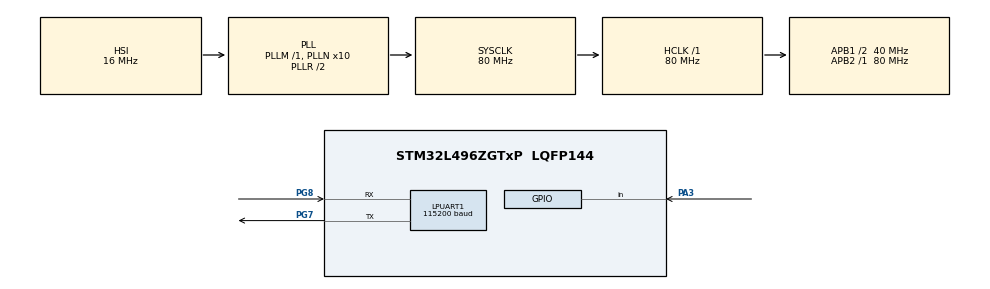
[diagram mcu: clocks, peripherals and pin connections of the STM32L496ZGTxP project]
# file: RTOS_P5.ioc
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FREERTOS.Mutexes01=myMutex01,Dynamic,NULL,Available
FREERTOS.RecursiveMutexes01=myRecursiveMutex01,Dynamic,NULL,Available
FREERTOS.Tasks01=LPT,16,512,StartLPT,Default,NULL,Dynamic,NULL,NULL;MPT,24,512,StartMPT,Default,NULL,Dynamic,NULL,NULL;HPT,32,512,StartHPT,Default,NULL,Dynamic,NULL,NULL;VHPT,40,512,StartVHPT,Default,NULL,Dynamic,NULL,NULL
FREERTOS.configTOTAL_HEAP_SIZE=10000
FREERTOS.configUSE_NEWLIB_REENTRANT=1
LPUART1.BaudRate=115200
LPUART1.WordLength=UART_WORDLENGTH_8B
Mcu.Family=STM32L4
Mcu.Name=STM32L496ZGTxP
Mcu.Package=LQFP144
NVIC.PriorityGroup=NVIC_PRIORITYGROUP_4
NVIC.TIM6_DAC_IRQn=true\:15\:0\:false\:false\:true\:false\:false\:true\:true
NVIC.TimeBase=TIM6_DAC_IRQn
NVIC.TimeBaseIP=TIM6
PA13\ (JTMS/SWDIO).Mode=Serial_Wire
PA13\ (JTMS/SWDIO).Signal=SYS_JTMS-SWDIO
PA14\ (JTCK/SWCLK).Mode=Serial_Wire
PA14\ (JTCK/SWCLK).Signal=SYS_JTCK-SWCLK
PA3.GPIO_PuPd=GPIO_PULLUP
PA3.Signal=GPIO_Input
PG7.Mode=Asynchronous
PG7.Signal=LPUART1_TX
PG8.Mode=Asynchronous
PG8.Signal=LPUART1_RX
ProjectManager.HeapSize=0x200
ProjectManager.StackSize=0x400
ProjectManager.TargetToolchain=STM32CubeIDE
RCC.48MHZClocksFreq_Value=24000000
RCC.ADCFreq_Value=64000000
RCC.AHBFreq_Value=80000000
RCC.APB1CLKDivider=RCC_HCLK_DIV2
RCC.APB1Freq_Value=40000000
RCC.APB1TimFreq_Value=80000000
RCC.APB2Freq_Value=80000000
RCC.APB2TimFreq_Value=80000000
RCC.CortexFreq_Value=80000000
RCC.HCLKFreq_Value=80000000
RCC.HSE_VALUE=8000000
RCC.HSI48_VALUE=48000000
RCC.HSI_VALUE=16000000
RCC.LSE_VALUE=32768
RCC.MSI_VALUE=4000000
RCC.PLLMUL=RCC_PLL_MUL9
RCC.PLLN=10
RCC.PLLSourceVirtual=RCC_PLLSOURCE_HSI
RCC.PRESCALERUSB=RCC_USBCLKSOURCE_PLL_DIV1_5
RCC.SYSCLKFreq_VALUE=80000000
RCC.SYSCLKSource=RCC_SYSCLKSOURCE_PLLCLK
RCC.SYSCLKSourceVirtual=RCC_SYSCLKSOURCE_PLLCLK
RCC.USBFreq_Value=64000000
RCC.VCOOutputFreq_Value=160000000
VP_FREERTOS_VS_CMSIS_V2.Mode=CMSIS_V2
VP_SYS_VS_tim6.Mode=TIM6
board=NUCLEO-L496ZG-P

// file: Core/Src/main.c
/* USER CODE BEGIN Header */
/**
  ******************************************************************************
  * @file           : main.c
  * @brief          : Main program body
  ******************************************************************************
  * @attention
  *
  * Copyright (c) 2026 STMicroelectronics.
  * All rights reserved.
  *
  * This software is licensed under terms that can be found in the LICENSE file
  * in the root directory of this software component.
  * If no LICENSE file comes with this software, it is provided AS-IS.
  *
  ******************************************************************************
  */
/* USER CODE END Header */
#include "main.h"
#include "cmsis_os.h"

/* USER CODE BEGIN Includes */
#include "stdio.h"
#include "string.h"
/* USER CODE END Includes */

UART_HandleTypeDef hlpuart1;

/* Definitions for LPT */
osThreadId_t LPTHandle;
const osThreadAttr_t LPT_attributes = {
  .name = "LPT",
  .stack_size = 512 * 4,
  .priority = (osPriority_t) osPriorityBelowNormal,
};
/* Definitions for MPT */
osThreadId_t MPTHandle;
const osThreadAttr_t MPT_attributes = {
  .name = "MPT",
  .stack_size = 512 * 4,
  .priority = (osPriority_t) osPriorityNormal,
};
/* Definitions for HPT */
osThreadId_t HPTHandle;
const osThreadAttr_t HPT_attributes = {
  .name = "HPT",
  .stack_size = 512 * 4,
  .priority = (osPriority_t) osPriorityAboveNormal,
};
/* Definitions for VHPT */
osThreadId_t VHPTHandle;
const osThreadAttr_t VHPT_attributes = {
  .name = "VHPT",
  .stack_size = 512 * 4,
  .priority = (osPriority_t) osPriorityHigh,
};
/* Definitions for myMutex01 */
osMutexId_t myMutex01Handle;
const osMutexAttr_t myMutex01_attributes = {
  .name = "myMutex01"
};
/* Definitions for myRecursiveMutex01 */
osMutexId_t myRecursiveMutex01Handle;
const osMutexAttr_t myRecursiveMutex01_attributes = {
  .name = "myRecursiveMutex01",
  .attr_bits = osMutexRecursive,
};

void SystemClock_Config(void);
static void MX_GPIO_Init(void);
static void MX_LPUART1_UART_Init(void);
void StartLPT(void *argument);
void StartMPT(void *argument);
void StartHPT(void *argument);
void StartVHPT(void *argument);

/* USER CODE BEGIN 0 */

int __io_putchar (int ch)
{
	uint8_t c = ch;
	HAL_UART_Transmit(&hlpuart1, &c, 1, HAL_MAX_DELAY);
	return ch;
}

/* USER CODE END 0 */

int main(void)
{

  /* MCU Configuration--------------------------------------------------------*/

  /* Reset of all peripherals, Initializes the Flash interface and the Systick. */
  HAL_Init();

  /* Configure the system clock */
  SystemClock_Config();

  /* Initialize all configured peripherals */
  MX_GPIO_Init();
  MX_LPUART1_UART_Init();

  /* Init scheduler */
  osKernelInitialize();
  /* Create the mutex(es) */
  /* creation of myMutex01 */
  myMutex01Handle = osMutexNew(&myMutex01_attributes);

  /* Create the recursive mutex(es) */
  /* creation of myRecursiveMutex01 */
  myRecursiveMutex01Handle = osMutexNew(&myRecursiveMutex01_attributes);

  /* Create the thread(s) */
  /* creation of LPT */
  LPTHandle = osThreadNew(StartLPT, NULL, &LPT_attributes);

  /* creation of MPT */
  MPTHandle = osThreadNew(StartMPT, NULL, &MPT_attributes);

  /* creation of HPT */
  HPTHandle = osThreadNew(StartHPT, NULL, &HPT_attributes);

  /* creation of VHPT */
  VHPTHandle = osThreadNew(StartVHPT, NULL, &VHPT_attributes);

  /* Start scheduler */
  osKernelStart();

  /* We should never get here as control is now taken by the scheduler */

  /* Infinite loop */
  while (1)
  {

  }
}

void SystemClock_Config(void)
{
  RCC_OscInitTypeDef RCC_OscInitStruct = {0};
  RCC_ClkInitTypeDef RCC_ClkInitStruct = {0};

  /** Configure the main internal regulator output voltage
  */
  if (HAL_PWREx_ControlVoltageScaling(PWR_REGULATOR_VOLTAGE_SCALE1) != HAL_OK)
  {
    Error_Handler();
  }

  /** Initializes the RCC Oscillators according to the specified parameters
  * in the RCC_OscInitTypeDef structure.
  */
  RCC_OscInitStruct.OscillatorType = RCC_OSCILLATORTYPE_HSI;
  RCC_OscInitStruct.HSIState = RCC_HSI_ON;
  RCC_OscInitStruct.HSICalibrationValue = RCC_HSICALIBRATION_DEFAULT;
  RCC_OscInitStruct.PLL.PLLState = RCC_PLL_ON;
  RCC_OscInitStruct.PLL.PLLSource = RCC_PLLSOURCE_HSI;
  RCC_OscInitStruct.PLL.PLLM = 1;
  RCC_OscInitStruct.PLL.PLLN = 10;
  RCC_OscInitStruct.PLL.PLLP = RCC_PLLP_DIV2;
  RCC_OscInitStruct.PLL.PLLQ = RCC_PLLQ_DIV2;
  RCC_OscInitStruct.PLL.PLLR = RCC_PLLR_DIV2;
  if (HAL_RCC_OscConfig(&RCC_OscInitStruct) != HAL_OK)
  {
    Error_Handler();
  }

  /** Initializes the CPU, AHB and APB buses clocks
  */
  RCC_ClkInitStruct.ClockType = RCC_CLOCKTYPE_HCLK|RCC_CLOCKTYPE_SYSCLK
                              |RCC_CLOCKTYPE_PCLK1|RCC_CLOCKTYPE_PCLK2;
  RCC_ClkInitStruct.SYSCLKSource = RCC_SYSCLKSOURCE_PLLCLK;
  RCC_ClkInitStruct.AHBCLKDivider = RCC_SYSCLK_DIV1;
  RCC_ClkInitStruct.APB1CLKDivider = RCC_HCLK_DIV2;
  RCC_ClkInitStruct.APB2CLKDivider = RCC_HCLK_DIV1;

  if (HAL_RCC_ClockConfig(&RCC_ClkInitStruct, FLASH_LATENCY_4) != HAL_OK)
  {
    Error_Handler();
  }
}

static void MX_LPUART1_UART_Init(void)
{

  hlpuart1.Instance = LPUART1;
  hlpuart1.Init.BaudRate = 115200;
  hlpuart1.Init.WordLength = UART_WORDLENGTH_8B;
  hlpuart1.Init.StopBits = UART_STOPBITS_1;
  hlpuart1.Init.Parity = UART_PARITY_NONE;
  hlpuart1.Init.Mode = UART_MODE_TX_RX;
  hlpuart1.Init.HwFlowCtl = UART_HWCONTROL_NONE;
  hlpuart1.Init.OneBitSampling = UART_ONE_BIT_SAMPLE_DISABLE;
  hlpuart1.AdvancedInit.AdvFeatureInit = UART_ADVFEATURE_NO_INIT;
  if (HAL_UART_Init(&hlpuart1) != HAL_OK)
  {
    Error_Handler();
  }

}

static void MX_GPIO_Init(void)
{
  GPIO_InitTypeDef GPIO_InitStruct = {0};

  /* GPIO Ports Clock Enable */
  __HAL_RCC_GPIOA_CLK_ENABLE();
  __HAL_RCC_GPIOG_CLK_ENABLE();
  HAL_PWREx_EnableVddIO2();

  /*Configure GPIO pin : PA3 */
  GPIO_InitStruct.Pin = GPIO_PIN_3;
  GPIO_InitStruct.Mode = GPIO_MODE_INPUT;
  GPIO_InitStruct.Pull = GPIO_PULLUP;
  HAL_GPIO_Init(GPIOA, &GPIO_InitStruct);

}

/* USER CODE BEGIN 4 */

void FunctionB(void)
{
    printf("FunctionB trying to lock mutex\n");
    osMutexAcquire(myRecursiveMutex01Handle, osWaitForever);
    printf("FunctionB acquired mutex\n");
    osDelay(100);
    osMutexRelease(myRecursiveMutex01Handle);
    printf("FunctionB released mutex\n");
}

void FunctionA(void)
{
    printf("FunctionA trying to lock mutex\n");
    osMutexAcquire(myRecursiveMutex01Handle, osWaitForever);
    printf("FunctionA acquired mutex\n");
    FunctionB();   // tries to lock the same mutex again
    osMutexRelease(myRecursiveMutex01Handle);
    printf("FunctionA released mutex\n\n");
}

/* USER CODE END 4 */

void StartLPT(void *argument)
{
  /* USER CODE BEGIN 5 */
 	uint32_t wait;
   /* Infinite loop */
   for(;;)
   {
	  printf ("Entered LPT, waiting for Mutex\n\n");
	  osMutexAcquire(myMutex01Handle, osWaitForever);
	  printf ("LPT Acquired Mutex, using Resource\n\n");
      wait = 10000000;
	  while (wait--);
	  printf ("LPT finished, released Mutex\n\n");
	  osMutexRelease(myMutex01Handle);
	  printf ("LPT going to Sleep\n\n");

	   // FunctionA();
 	  // osDelay(5000);
   }
  /* USER CODE END 5 */
}

void StartMPT(void *argument)
{
  /* USER CODE BEGIN StartMPT */
 	uint32_t wait;
   /* Infinite loop */
   for(;;)
   {
	  printf ("Entered MPT, performing task\n\n");
	  wait = 50000000;
	  while (wait--);
	  printf ("MPT finished, going to Sleep\n\n");
 	  osDelay(500);
   }
  /* USER CODE END StartMPT */
}

void StartHPT(void *argument)
{
  /* USER CODE BEGIN StartHPT */

   /* Infinite loop */
   for(;;)
   {
	  printf ("Entered HPT, waiting for Mutex\n\n");
	  osMutexAcquire(myMutex01Handle, osWaitForever);
	  printf ("HPT Acquired and now releasing Mutex\n\n");
	  osMutexRelease(myMutex01Handle);
	  printf ("HPT going to Sleep\n\n");
 	  osDelay(200);
   }
  /* USER CODE END StartHPT */
}

void StartVHPT(void *argument)
{
  /* USER CODE BEGIN StartVHPT */
  /* Infinite loop */
  for(;;)
  {
	  printf("Priorities ->-> LPT:%d MPT:%d HPT:%d\n\n",
	          osThreadGetPriority(LPTHandle),
	          osThreadGetPriority(MPTHandle),
	          osThreadGetPriority(HPTHandle));
      osDelay(50);
  }
  /* USER CODE END StartVHPT */
}

void HAL_TIM_PeriodElapsedCallback(TIM_HandleTypeDef *htim)
{
  if (htim->Instance == TIM6)
  {
    HAL_IncTick();
  }
}

void Error_Handler(void)
{
  __disable_irq();
  while (1)
  {
  }
}
